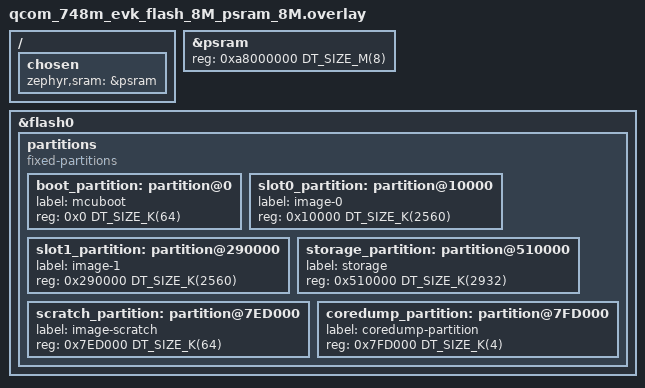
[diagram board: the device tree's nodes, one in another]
/*
 * Copyright (c) 2026 Qualcomm Technologies, Inc. and/or its subsidiaries
 *
 * SPDX-License-Identifier: Apache-2.0
 */

/* 8 MB PSRAM variant of QCC748M EVK */
&psram {
	status = "okay";
	reg = <0xa8000000 DT_SIZE_M(8)>;
};

/ {
	chosen {
		zephyr,sram = &psram;
	};
};

&flash0 {
	/delete-node/ partitions;

	partitions {
		compatible = "fixed-partitions";
		#address-cells = <1>;
		#size-cells = <1>;

		boot_partition: partition@0 {
			label = "mcuboot";
			reg = <0x0 DT_SIZE_K(64)>;
		};

		slot0_partition: partition@10000 {
			label = "image-0";
			reg = <0x10000 DT_SIZE_K(2560)>;
		};

		slot1_partition: partition@290000 {
			label = "image-1";
			reg = <0x290000 DT_SIZE_K(2560)>;
		};

		storage_partition: partition@510000 {
			label = "storage";
			reg = <0x510000 DT_SIZE_K(2932)>;
		};

		scratch_partition: partition@7ED000 {
			label = "image-scratch";
			reg = <0x7ED000 DT_SIZE_K(64)>;
		};

		coredump_partition: partition@7FD000 {
			label = "coredump-partition";
			reg = <0x7FD000 DT_SIZE_K(4)>;
		};
	};
};
